AUTOSAR XML (schema 00046)
package /Runnable_lab1
  sender reciever interface SRI_Throttle
    data CMD: type=uint32
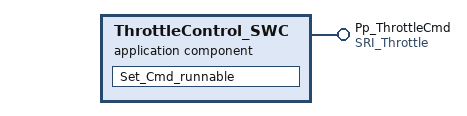
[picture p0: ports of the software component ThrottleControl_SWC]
  application sw component type ThrottleControl_SWC
    provide port Pp_ThrottleCmd: provided-interface=SRI_Throttle
    behavior ThController-behav
      runnable Set_Cmd_runnable: symbol=Set_Cmd
        data-write-access:
          access CMD_data: accessed-variable=Pp_ThrottleCmd.CMD
